# ATSAM4LS8A register map
Vendor: Atmel Corporation; Series: SAM4L; File version: A
CPU: CM4 r0p1, little endian, MPU, no FPU, 4 interrupt priority bits
Registers are 32-bit, write-only, reset 0x0 unless marked. A register's access mark holds for its fields unless they carry their own. Offsets are from the block's base; [hi:lo] are bit positions; {n}, {i} and the like mark numbered series; 'fields as' and 'values as' point back to an identical list.

## BSCIF — Backup System Control Interface
Base 0x400F0400; register names take the prefix BSCIF_
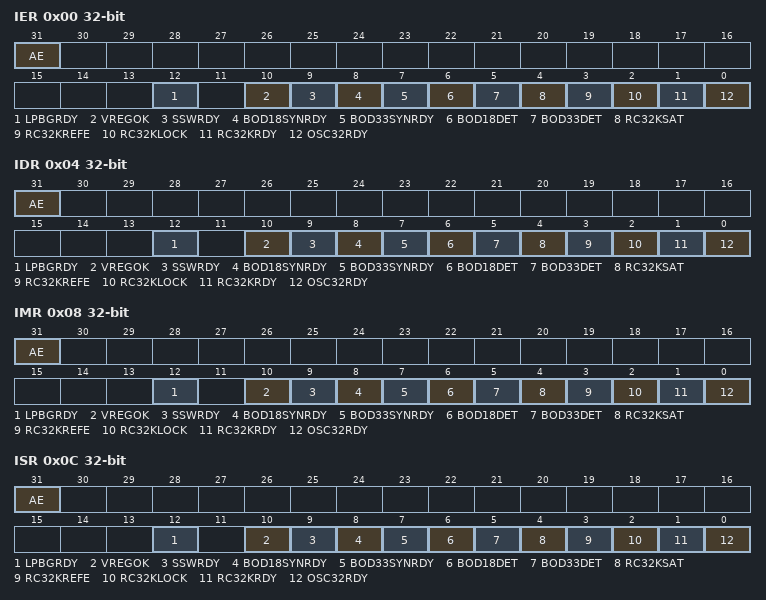
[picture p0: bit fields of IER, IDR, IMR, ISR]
0x00 IER — Interrupt Enable Register
  [31] AE — Access Error
  [12] LPBGRDY — Low Power Bandgap Voltage Reference Ready
  [10] VREGOK — Main VREG OK
  [9] SSWRDY — VREG Stop Switching Ready
  [8] BOD18SYNRDY — BOD18 Synchronization Ready
  [7] BOD33SYNRDY — BOD33 Synchronization Ready
  [6] BOD18DET — BOD18 Detected
  [5] BOD33DET — BOD33 Detected
  [4] RC32KSAT — 32kHz RC Oscillator Saturation
  [3] RC32KREFE — 32kHz RC Oscillator Reference Error
  [2] RC32KLOCK — 32kHz RC Oscillator Lock
  [1] RC32KRDY — 32kHz RC Oscillator Ready
  [0] OSC32RDY — 32kHz Oscillator Ready
0x04 IDR — Interrupt Disable Register
  [31] AE — Access Error
  [12] LPBGRDY — Low Power Bandgap Voltage Reference Ready
  [10] VREGOK — Mai n VREG OK
  [9] SSWRDY — VREG Stop Switching Ready
  [8] BOD18SYNRDY — BOD18 Synchronization Ready
  [7] BOD33SYNRDY — BOD33 Synchronization Ready
  [6] BOD18DET — BOD18 Detected
  [5] BOD33DET — BOD33 Detected
  [4] RC32KSAT — 32kHz RC Oscillator Saturation
  [3] RC32KREFE — 32kHz RC Oscillator Reference Error
  [2] RC32KLOCK — 32kHz RC Oscillator Lock
  [1] RC32KRDY — 32kHz RC Oscillator Ready
  [0] OSC32RDY — 32kHz Oscillator Ready
0x08 IMR ro — Interrupt Mask Register
  fields as IER
0x0C ISR ro — Interrupt Status Register
  fields as IER
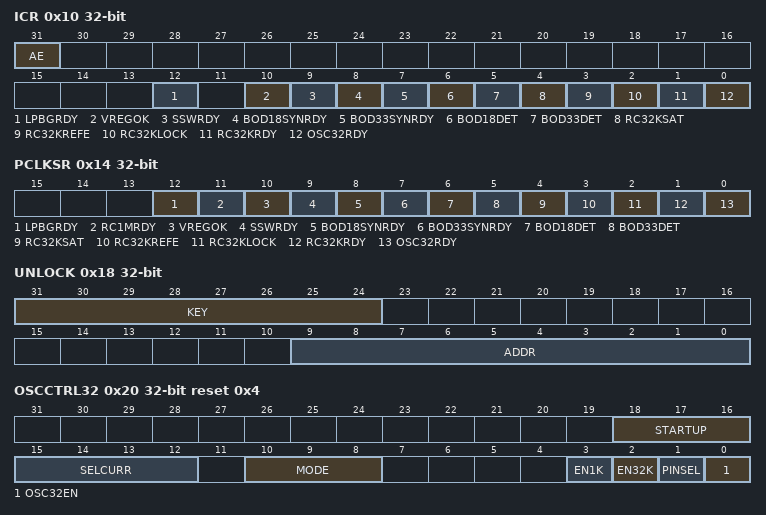
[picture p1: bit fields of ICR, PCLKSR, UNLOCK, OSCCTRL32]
0x10 ICR — Interrupt Clear Register
  fields as IER
0x14 PCLKSR ro — Power and Clocks Status Register
  [12] LPBGRDY — Low Power Bandgap Voltage Reference Ready
  [11] RC1MRDY — RC 1MHz Oscillator Ready
  [10] VREGOK — Main VREG OK
  [9] SSWRDY — VREG Stop Switching Ready
  [8] BOD18SYNRDY — BOD18 Synchronization Ready
  [7] BOD33SYNRDY — BOD33 Synchronization Ready
  [6] BOD18DET — BOD18 Detected
  [5] BOD33DET — BOD33 Detected
  [4] RC32KSAT — 32kHz RC Oscillator Saturation
  [3] RC32KREFE — 32kHz RC Oscillator Reference Error
  [2] RC32KLOCK — 32kHz RC Oscillator Lock
  [1] RC32KRDY — 32kHz RC Oscillator Ready
  [0] OSC32RDY — 32kHz Oscillator Ready
0x18 UNLOCK
  [31:24] KEY — Unlock Key
    170=VALID (Valid Key to Unlock register)
  [9:0] ADDR — Unlock Address
0x1C CSCR rw — Chip Specific Configuration Register
0x20 OSCCTRL32 rw reset 0x4 — Oscillator 32 Control Register
  [18:16] STARTUP — Oscillator Start-up Time
  [15:12] SELCURR — Current selection
  [10:8] MODE — Oscillator Mode
  [3] EN1K — 1 KHz output Enable
  [2] EN32K — 32 KHz output Enable
  [1] PINSEL — Pins Select
  [0] OSC32EN — 32 KHz Oscillator Enable
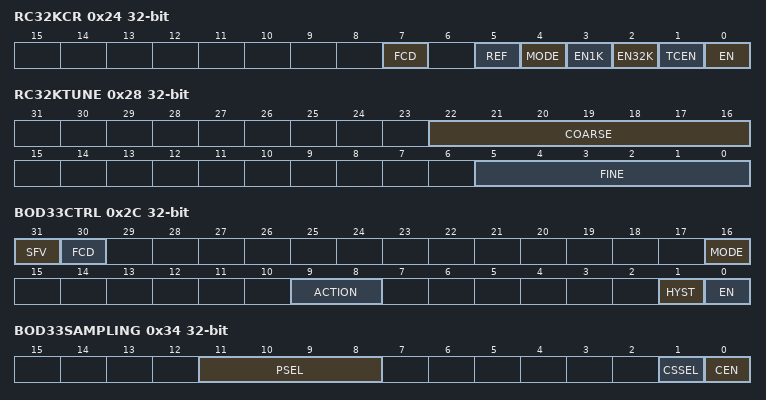
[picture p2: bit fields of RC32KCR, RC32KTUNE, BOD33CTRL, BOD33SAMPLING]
0x24 RC32KCR rw — 32 kHz RC Oscillator Control Register
  [7] FCD — Flash calibration done
  [5] REF — Reference select
  [4] MODE — Mode Selection
  [3] EN1K — Enable 1 kHz output
  [2] EN32K — Enable 32 KHz output
  [1] TCEN — Temperature Compensation Enable
  [0] EN — Enable as Generic clock source
0x28 RC32KTUNE rw — 32kHz RC Oscillator Tuning Register
  [22:16] COARSE — Coarse Value
  [5:0] FINE — Fine value
0x2C BOD33CTRL rw — BOD33 Control Register
  [31] SFV — BOD Control Register Store Final Value
  [30] FCD — BOD Fuse Calibration Done
  [16] MODE — Operation modes
  [9:8] ACTION
  [1] HYST — BOD Hysteresis
  [0] EN — Enable
0x30 BOD33LEVEL rw
  [5:0] VAL — BOD Value
0x34 BOD33SAMPLING rw — BOD33 Sampling Control Register
  [11:8] PSEL — Prescaler Select
  [1] CSSEL — Clock Source Select
  [0] CEN — Clock Enable
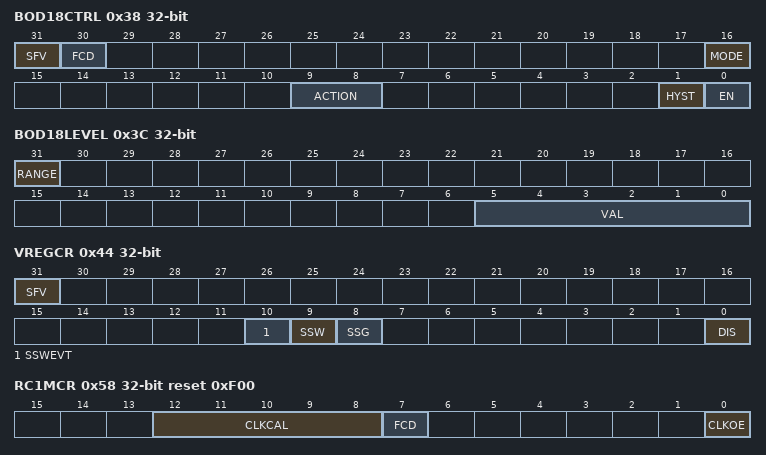
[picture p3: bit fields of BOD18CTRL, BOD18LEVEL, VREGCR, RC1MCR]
0x38 BOD18CTRL rw — BOD18 Control Register
  fields as BOD33CTRL
0x3C BOD18LEVEL rw
  [31] RANGE — BOD Threshold Range
  [5:0] VAL — BOD Value
0x44 VREGCR rw — Voltage Regulator Configuration Register
  [31] SFV — Store Final Value
  [10] SSWEVT — Stop Switching On Event Enable
  [9] SSW — Stop Switching
  [8] SSG — Spread Spectrum Generator Enable
  [0] DIS — Voltage Regulator disable
0x4C VREGNCSR rw — Normal Mode Control and Status Register
0x50 VREGLPCSR rw — LP Mode Control and Status Register
0x58 RC1MCR rw reset 0xF00 — 1MHz RC Clock Configuration Register
  [12:8] CLKCAL — 1MHz RC Osc Calibration
  [7] FCD — Flash Calibration Done
  [0] CLKOE — 1MHz RC Osc Clock Output Enable
0x5C BGCR rw — Bandgap Calibration Register
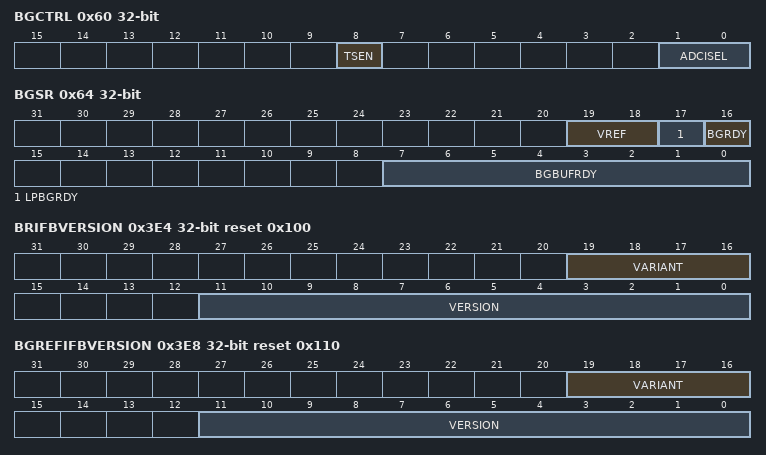
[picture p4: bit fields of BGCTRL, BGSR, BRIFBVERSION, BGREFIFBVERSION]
0x60 BGCTRL rw — Bandgap Control Register
  [8] TSEN — Temperature Sensor Enable
  [1:0] ADCISEL — ADC Input Selection
    0=DIS; 1=VTEMP; 2=VREF
0x64 BGSR ro — Bandgap Status Register
  [19:18] VREF — Voltage Reference Used by the System
  [17] LPBGRDY — Low Power Bandgap Voltage Reference Ready
  [16] BGRDY — Bandgap Voltage Reference Ready
  [7:0] BGBUFRDY — Bandgap Buffer Ready
    1=FLASH; 2=PLL; 4=VREG; 8=BUFRR; 16=ADC; 32=LCD
{0x78+4i} BR{i} (i=0..3) rw — Backup Register
0x3E4 BRIFBVERSION ro reset 0x100 — Backup Register Interface Version Register
  [19:16] VARIANT — Variant Number
  [11:0] VERSION — Version Number
0x3E8 BGREFIFBVERSION ro reset 0x110
  [19:16] VARIANT — Variant Number
  [11:0] VERSION — Version Number
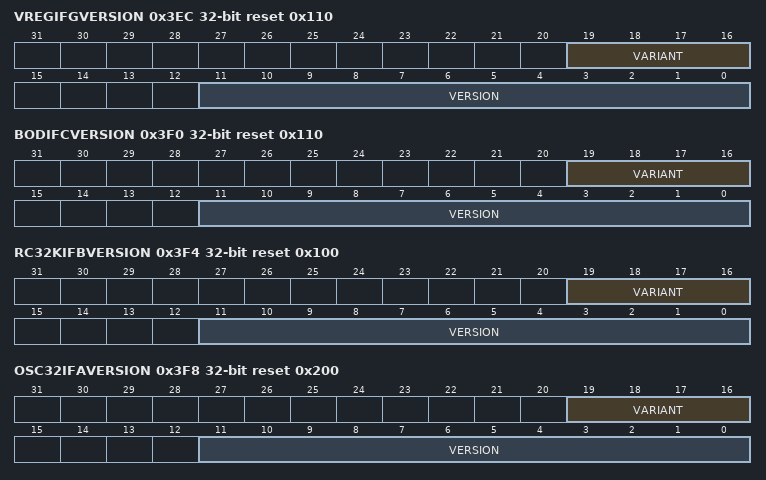
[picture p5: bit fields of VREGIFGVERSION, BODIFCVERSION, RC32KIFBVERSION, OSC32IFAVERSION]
0x3EC VREGIFGVERSION ro reset 0x110 — VREGIFA Version Register
  [19:16] VARIANT — Variant Number
  [11:0] VERSION — Version Number
0x3F0 BODIFCVERSION ro reset 0x110
  [19:16] VARIANT — Variant Number
  [11:0] VERSION — Version Number
0x3F4 RC32KIFBVERSION ro reset 0x100 — 32 kHz RC Oscillator Version Register
  [19:16] VARIANT — Variant number
  [11:0] VERSION — Version number
0x3F8 OSC32IFAVERSION ro reset 0x200 — 32 KHz Oscillator Version Register
  [19:16] VARIANT — Variant nubmer
  [11:0] VERSION — Version number
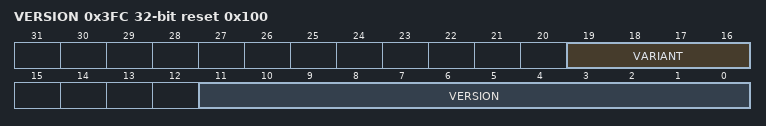
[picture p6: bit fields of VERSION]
0x3FC VERSION ro reset 0x100 — BSCIF Version Register
  [19:16] VARIANT — Variant Number
  [11:0] VERSION — Version Number

## Notices in the file
Atmel Microcontroller Software Support
Copyright (c) 2014, Atmel Corporation
All rights reserved.
Redistribution and use in source and binary forms, with or without
modification, are permitted provided that the following condition is met:
- Redistributions of source code must retain the above copyright notice,
this list of conditions and the disclaimer below.
Atmel's name may not be used to endorse or promote products derived from
this software without specific prior written permission.
DISCLAIMER: THIS SOFTWARE IS PROVIDED BY ATMEL "AS IS" AND ANY EXPRESS OR
IMPLIED WARRANTIES, INCLUDING, BUT NOT LIMITED TO, THE IMPLIED WARRANTIES OF
MERCHANTABILITY, FITNESS FOR A PARTICULAR PURPOSE AND NON-INFRINGEMENT ARE
DISCLAIMED. IN NO EVENT SHALL ATMEL BE LIABLE FOR ANY DIRECT, INDIRECT,
INCIDENTAL, SPECIAL, EXEMPLARY, OR CONSEQUENTIAL DAMAGES (INCLUDING, BUT NOT
LIMITED TO, PROCUREMENT OF SUBSTITUTE GOODS OR SERVICES; LOSS OF USE, DATA,
OR PROFITS; OR BUSINESS INTERRUPTION) HOWEVER CAUSED AND ON ANY THEORY OF
LIABILITY, WHETHER IN CONTRACT, STRICT LIABILITY, OR TORT (INCLUDING
NEGLIGENCE OR OTHERWISE) ARISING IN ANY WAY OUT OF THE USE OF THIS SOFTWARE,
EVEN IF ADVISED OF THE POSSIBILITY OF SUCH DAMAGE.
